# ISD91200B_v1 register map
File version: 1.0
Registers are 32-bit, read-write, reset 0x0 unless marked. A register's access mark holds for its fields unless they carry their own. Offsets are from the block's base; [hi:lo] are bit positions; <NAME> marks a mode.

## CSCAN — CSCAN Register Map
Base 0x400D0000
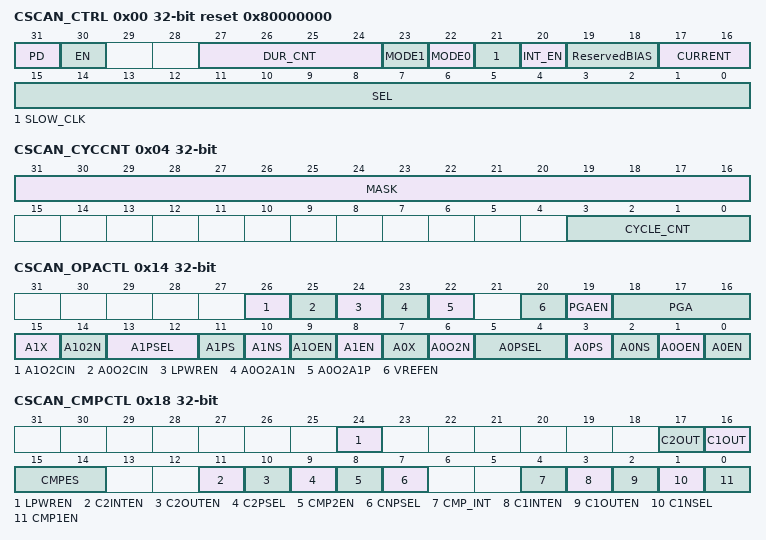
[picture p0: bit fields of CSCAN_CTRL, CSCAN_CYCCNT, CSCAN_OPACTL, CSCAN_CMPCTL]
0x00 CSCAN_CTRL reset 0x80000000 — CSCAN Control Register
  [31] PD — Power Down. 0: Enable analog circuit. 1: Power down analog circuit and block.
  [30] EN — CSCAN Enable. Write 1 to start. Reset by hardware when operation finished.
  [27:24] DUR_CNT — CSCAN Duration Count. This counter is used to set a wakeup time after a capacitive sensing scan is complete. It is in units of low frewquency clock period (either LXT or LIRC clock) and gives delay of 160, 320, 480,640, 800, 960, 1120, 1280, 1440,1600, 1920, 2240, 2560, 2880,3200 3840 periods for settings 0,..,15.
  [23] MODE1 — CSCAN Mode1
    0=Interrupt when scan finished; 1=Interrupt when DUR_CNT delay occurs
  [22] MODE0 — CSCAN Mode0
    0=Single shot Capacitive sense; 1=Scans each channel set in SCAN_MASK and stores in RAM
  [21] SLOW_CLK — CSCAN Slow Clock **Notes: In low speed mode, for CYCLE_CNT <5, the minimum frequency of oscillation of a CAPSENSE GPIO must be > Fclk/2. Where Fclk is the frequency of LXT or LIRC depending which is selected as reference.
    0=Timebase clock is HIRC; 1=Timebase clock is LIRC (XTAL32K_EN = 0) or XTAL (XTAL32K_EN = 1)
  [20] INT_EN — CSCAN Enable Interrupt
    0=Interrupt disabled; 1=Interrupt enabled
  [19:18] ReservedBIAS — CSCAN Comparator bias current. Controls the bais current of relaxation comparators. Suggest default 0. Can select lower for marginal power savings and less accuracy. 0:Normal 1:Half 3:Quarter. Keep with 0
  [17:16] CURRENT — CSCAN Oscillator current. Controls the analog bais current of the capacitive relaxation oscillator. 0:300nA 1:450nA 2:600nA 3:1200nA
  [15:0] SEL — CSCAN Select. In single mode selects the channel (GPIOB[15:0]) to perform measurement on.
0x04 CSCAN_CYCCNT — CSCAN Cycle Count Control Register
  [31:16] MASK — Scan Mask Register. If MASK[n] is set then GPIOB[n] is included in scan of capacitive sensing.
  [3:0] CYCLE_CNT — CSCAN Cycle Count
0x08 CSCAN_COUNT — CSCAN Count Status Register
  [15:0] COUNT — CSCAN Count. Count result of single scan.
0x0C CSCAN_INT — CSCAN Interrupt Register
  [0] INT — CSCAN Interrupt active. Write '1' to clear.
0x10 CSCAN_AGPIO — CSCAN Analog GPIO Function Register
  [15:0] AGPIO — CSCAN AGPIO. If bit set to 1 then corresponding GPIOB[n] is forced to an analog mode where digital input, output and pullup is disabled. Can be used to set pad into analog mode for CapSensing, SAR ADC and OPAMP functions.
0x14 CSCAN_OPACTL — Operational Amplifier Control Register
  [26] A1O2CIN — OPA1 output to comparator input control bit
    0=disable; 1=enable
  [25] A0O2CIN — OPA0 output to comparator input control bit
    0=disable; 1=enable
  [24] LPWREN — Enable Opamps in STOP/SPD modes
    0=disable; 1=enable
  [23] A0O2A1N — OPA0 Output to OPA0 Inverting Input Control Bit
    0=disable; 1=enable
  [22] A0O2A1P — OPA0 Output to OPA1 Non-inverting Input Control Bit
    0=disable; 1=enable
  [20] VREFEN — Enable OPA and Comparator Reference Voltage Generator
    0=disable; 1=enable
  [19] PGAEN — OPA1 PGA Gain Enable Control Bits
    0=disable; 1=Enable
  [18:16] PGA — OPA1 Gain Control Bits
    0=1; 1=8; 2=16; 3=24; 4=32; 5=40; 6=48; 7=56
  [15] A1X — Operational amplifier 1 output; positive logic This bit is read only
  [14] A102N — OPA1 Output to OPA1 Inverting Input Control Bit
    0=disable; 1=enable
  [13:12] A1PSEL — OPA1 Non-inverting Input Selection Bit
    0=no connection; 1=from VH1 (0.9×VDDA); 2=from VM (0.5×VDDA ); 3=: from VL1 (0.1×VDDA)
  [11] A1PS — A1P Pin to OPA1 Non-inverting Input Control Bit
    0=no connection; 1=from A0P pin
  [10] A1NS — A1N Pin to OPA1 Inverting Input Control Bit
    0=no connection; 1=from A0N pin
  [9] A1OEN — OPA1 Output Enable or Disable Control Bit
    0=disable; 1=enable
  [8] A1EN — OPA1 Enable or Disable Control Bit
    0=disable; 1=enable
  [7] A0X — Operational amplifier 0 output; positive logic This bit is read only
  [6] A0O2N — OPA0 Output to OPA0 Inverting Input Control Bit
    0=disable; 1=enable
  [5:4] A0PSEL — OPA0 Non-inverting Input Selection Bit
    0=no connection; 1=from VH1 (0.9×VDDA); 2=from VM (0.5×VDDA); 3=: from VL1 (0.1×VDDA)
  [3] A0PS — A0P Pin to OPA0 Non-inverting Input Control Bit
    0=no connection; 1=from A0P pin
  [2] A0NS — A0N Pin to OPA0 Inverting Input Control Bit
    0=no connection; 1=from A0N pin
  [1] A0OEN — OPA0 Output Enable or Disable Control Bit
    0=disable; 1=enable
  [0] A0EN — OPA0 Enable or Disable Control Bit
    0=disable; 1=enable
0x18 CSCAN_CMPCTL — Comparator Control Register
  [24] LPWREN — Comparator Low power mode enable. If '1' comparator will remain enabled in STOP/SPD power modes.
  [17] C2OUT — Comparator 2 Output. Real time readback of comparator 2.
  [16] C1OUT — Comparator 1 Output. Real time readback of comparator 1.
  [15:14] CMPES — Interrupt edge control bits
    0=disable; 1=rising edge trigger; 2=falling edge trigger; 3=dual edge trigger
  [11] C2INTEN — Comparator 2 interrupt control
    0=disable; 1=enable
  [10] C2OUTEN — Comparator 2 output pin control bit
    0=disable; 1=enable
  [9] C2PSEL — Comparator 2 inverting input control
    0=from VL0; 1=from C2P pin
  [8] CMP2EN — Comparator 2 enable or disable control
    0=disable; 1=enable
  [7] CNPSEL — Comparator non-inverting input control
    0=from OPA output; 1=from CNP pin
  [4] CMP_INT — Comparator Interrupt. Set by harddware. Write 1 to clear.
  [3] C1INTEN — Comparator 1 interrupt control
    0=disable; 1=enable
  [2] C1OUTEN — Comparator 1 output pin control bit
    0=disable; 1=enable
  [1] C1NSEL — Comparator 1 inverting input control
    0=from VH0; 1=from C1N pin
  [0] CMP1EN — Comparator 1 enable or disable control
    0=disable; 1=enable
